# AT32M412xx_v2 register map
Vendor: Keil; Series: AT32M412; File version: 1.0
CPU: CM4 r0p1, little endian, no MPU, FPU, 4 interrupt priority bits
Registers are 32-bit, read-write, reset 0x0 unless marked. A register's access mark holds for its fields unless they carry their own. Offsets are from the block's base; [hi:lo] are bit positions; {n}, {i} and the like mark numbered series.

## USB_OTGFS_PWRCLK — USB on the go full speed
Base 0x50000E00
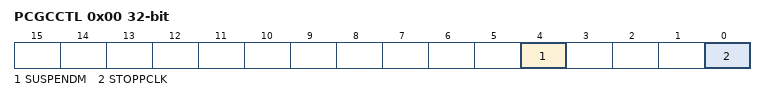
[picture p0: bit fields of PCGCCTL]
0x00 PCGCCTL — OTGFS power and clock gating control register (OTGFS_PCGCCTL)
  [4] SUSPENDM ro — PHY Suspended
  [0] STOPPCLK — Stop PHY clock

## SCFG — System configuration controller
Base 0x40013800
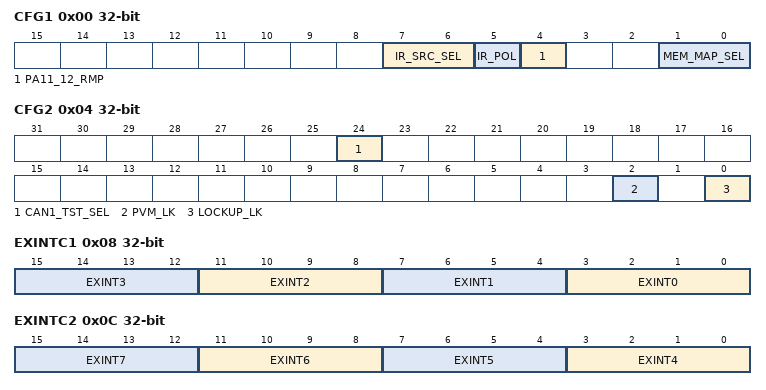
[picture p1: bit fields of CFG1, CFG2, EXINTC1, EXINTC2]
0x00 CFG1 — configuration register 1
  [7:6] IR_SRC_SEL — IR signal source selection
  [5] IR_POL — IR output polarity selection
  [4] PA11_12_RMP — PA11_12 remap to PA9_10 enable
  [1:0] MEM_MAP_SEL — Memory address mapping selection bits
0x04 CFG2 — configuration register 2
  [24] CAN1_TST_SEL — CAN timestamp clock source selection
  [2] PVM_LK — PVM lock enable
  [0] LOCKUP_LK — CM4 LOCKUP bit enable
0x08 EXINTC1 — external interrupt configuration register 1
  [4n+3:4n] EXINT{n} (n=0..3) — EXINT {n} configuration bits
0x0C EXINTC2 — external interrupt configuration register 2
  [4n-13:4n-16] EXINT{n} (n=4..7) — EXINT {n} configuration bits
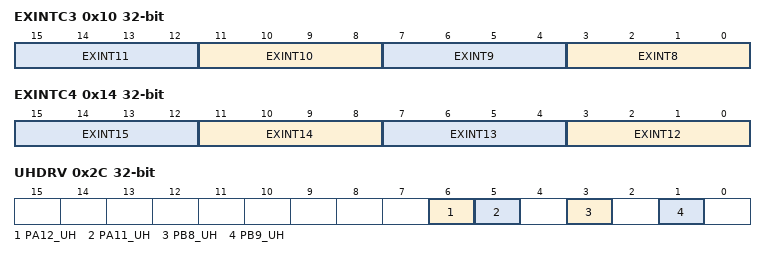
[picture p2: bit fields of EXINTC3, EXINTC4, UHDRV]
0x10 EXINTC3 — external interrupt configuration register 3
  [4n-29:4n-32] EXINT{n} (n=8..11) — EXINT {n} configuration bits
0x14 EXINTC4 — external interrupt configuration register 4
  [4n-45:4n-48] EXINT{n} (n=12..15) — EXINT {n} configuration bits
0x2C UHDRV — Ultra high drive register
  [6] PA12_UH — PA12 ultra high sourcing/sinking strength
  [5] PA11_UH — PA11 ultra high sourcing/sinking strength
  [3] PB8_UH — PB8 ultra high sourcing/sinking strength
  [1] PB9_UH — PB9 ultra high sourcing/sinking strength
0x60 IOCFG — IO config register
  [0] NRST_RMP — NRST pin remap selection
0x64 IOKEY — IO config key register
  [15:0] IOKEY — IO config key

## OP — Operational amplifiers
Base 0x40013B00
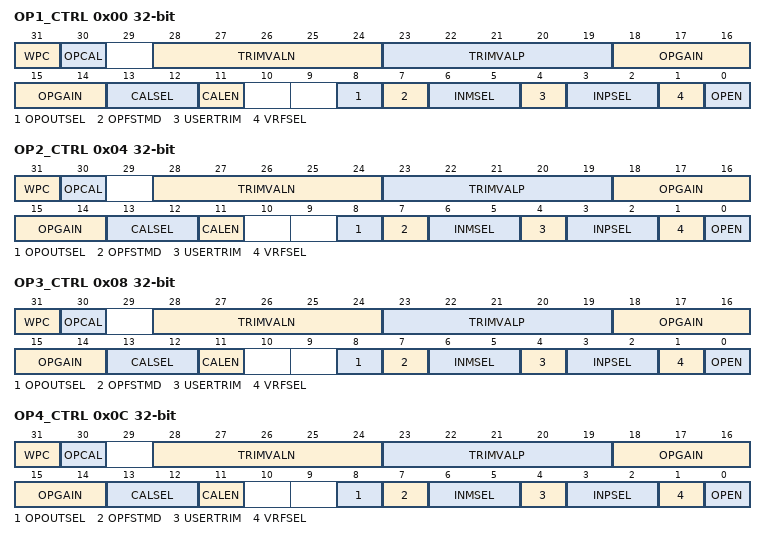
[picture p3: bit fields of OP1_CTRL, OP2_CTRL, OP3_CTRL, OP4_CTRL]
0x00 OP1_CTRL — OP1 control/status register
  [31] WPC — OP1_CTRL write protected configuration
  [30] OPCAL — Operational amplifier calibration output
  [28:24] TRIMVALN — Trim for NMOS differential pairs
  [23:19] TRIMVALP — Trim for PMOS differential pairs
  [18:14] OPGAIN — Operational amplifier Programmable amplifier gain value
  [13:12] CALSEL — Calibration selection
  [11] CALEN — Calibration mode enabled
  [8] OPOUTSEL — Operational amplifier internal output enable
  [7] OPFSTMD — Operational amplifier fast mode
  [6:5] INMSEL — Inverting input selection
  [4] USERTRIM — User trimming enable
  [3:2] INPSEL — Non inverted input selection
  [1] VRFSEL — Force internal reference on OP VINP input
  [0] OPEN — Operational amplifier Enable
0x04 OP2_CTRL — OP2 control/status register
  [31] WPC — OP2_CTRL write protected configuration
  [30] OPCAL — Operational amplifier calibration output
  [28:24] TRIMVALN — Trim for NMOS differential pairs
  [23:19] TRIMVALP — Trim for PMOS differential pairs
  [18:14] OPGAIN — Operational amplifier Programmable amplifier gain value
  [13:12] CALSEL — Calibration selection
  [11] CALEN — Calibration mode enabled
  [8] OPOUTSEL — Operational amplifier internal output enable
  [7] OPFSTMD — Operational amplifier fast mode
  [6:5] INMSEL — Inverting input selection
  [4] USERTRIM — User trimming enable
  [3:2] INPSEL — Non inverted input selection
  [1] VRFSEL — Force internal reference on OP VINP input
  [0] OPEN — Operational amplifier Enable
0x08 OP3_CTRL — OP3 control/status register
  [31] WPC — OP3_CTRL write protected configuration
  [30] OPCAL — Operational amplifier calibration output
  [28:24] TRIMVALN — Trim for NMOS differential pairs
  [23:19] TRIMVALP — Trim for PMOS differential pairs
  [18:14] OPGAIN — Operational amplifier Programmable amplifier gain value
  [13:12] CALSEL — Calibration selection
  [11] CALEN — Calibration mode enabled
  [8] OPOUTSEL — Operational amplifier internal output enable
  [7] OPFSTMD — Operational amplifier fast mode
  [6:5] INMSEL — Inverting input selection
  [4] USERTRIM — User trimming enable
  [3:2] INPSEL — Non inverted input selection
  [1] VRFSEL — Force internal reference on OP VINP input
  [0] OPEN — Operational amplifier Enable
0x0C OP4_CTRL — OP4 control/status register
  [31] WPC — OP4_CTRL write protected configuration
  [30] OPCAL — Operational amplifier calibration output
  [28:24] TRIMVALN — Trim for NMOS differential pairs
  [23:19] TRIMVALP — Trim for PMOS differential pairs
  [18:14] OPGAIN — Operational amplifier Programmable amplifier gain value
  [13:12] CALSEL — Calibration selection
  [11] CALEN — Calibration mode enabled
  [8] OPOUTSEL — Operational amplifier internal output enable
  [7] OPFSTMD — Operational amplifier fast mode
  [6:5] INMSEL — Inverting input selection
  [4] USERTRIM — User trimming enable
  [3:2] INPSEL — Non inverted input selection
  [1] VRFSEL — Force internal reference on OP VINP input
  [0] OPEN — Operational amplifier Enable
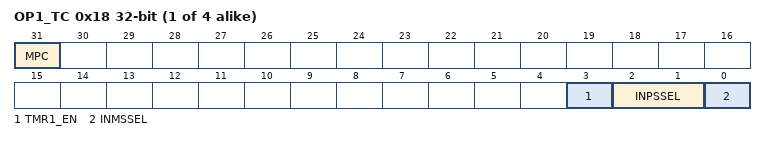
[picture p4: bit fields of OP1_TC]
{0x14+4i} OP{i}_TC (i=1..4) — OP{i} timer controlled mode register
  [31] MPC — OP{i}_TC write protected configuration
  [3] TMR1_EN — TMR1 controlled mux mode enable
  [2:1] INPSSEL — OP1 Non inverting input secondary selection
  [0] INMSSEL — OP1 inverting input secondary selection

## QSPI1 — Quad SPI Controller
Base 0xA0001000
Same registers: QSPI2 0xA0002000
0x00 CMD_W0 — Command word 0
  [31:0] SPIADR — SPI flash address
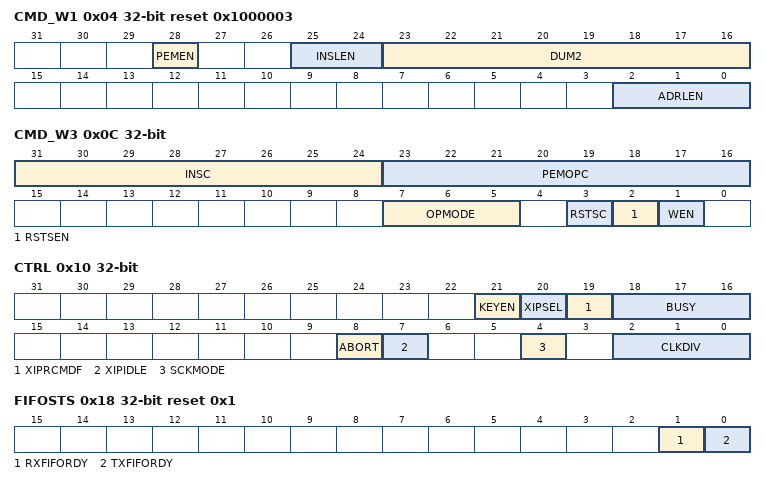
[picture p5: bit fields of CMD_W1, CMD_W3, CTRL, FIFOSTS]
0x04 CMD_W1 reset 0x1000003 — Command word 1
  [28] PEMEN — Perfrmance enhance mode enable
  [25:24] INSLEN — Instruction code length
  [23:16] DUM2 — Second dummy state cycle
  [2:0] ADRLEN — SPI address length
0x08 CMD_W2 reset 0x1000003 — Command word 2
  [31:0] DCNT — Read write data counter
0x0C CMD_W3 — Command word 3
  [31:24] INSC — Instruction code
  [23:16] PEMOPC — Performance enhance mode operate code
  [7:5] OPMODE — SPI operate mode
  [3] RSTSC — Read spi status configure
  [2] RSTSEN — Read spi status enable
  [1] WEN — Write data enable
0x10 CTRL — Control register
  [21] KEYEN — encryption key enable
  [20] XIPSEL — XIP port selection
  [19] XIPRCMDF — XIP read command flush
  [18:16] BUSY — Busy bit of spi status
  [8] ABORT — Abort instruction
  [7] XIPIDLE — XIP port idle status
  [4] SCKMODE — Sckout mode
  [2:0] CLKDIV — SPI clock divider
0x14 ACTR reset 0xF — AC timing control register
  [3:0] CSDLY — CS delay
0x18 FIFOSTS ro reset 0x1 — FIFO Status register
  [1] RXFIFORDY — RxFIFO ready status
  [0] TXFIFORDY — TxFIFO ready status
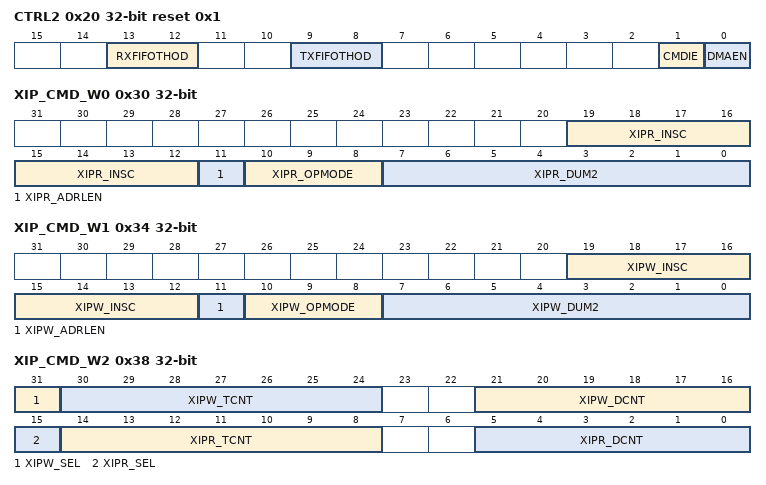
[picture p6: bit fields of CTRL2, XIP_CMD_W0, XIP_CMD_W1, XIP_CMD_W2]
0x20 CTRL2 reset 0x1 — control register 2
  [13:12] RXFIFOTHOD
  [9:8] TXFIFOTHOD
  [1] CMDIE — Command complete interrupt enable
  [0] DMAEN — DMA handshake enable
0x24 CMDSTS ro — CMD status register
  [0] CMDSTS — Command complete status
0x28 RSTS ro — SPI read status register
  [7:0] SPISTS — SPI read status
0x2C FSIZE — SPI flash size
  [31:0] SPIFSIZE
0x30 XIP_CMD_W0 — XIP command word 0
  [19:12] XIPR_INSC — XIP read instruction code
  [11] XIPR_ADRLEN — XIP read address length
  [10:8] XIPR_OPMODE — XIP read operate mode
  [7:0] XIPR_DUM2 — XIP read second dummy cycle
0x34 XIP_CMD_W1 — XIP command word 1
  [19:12] XIPW_INSC — XIP write instruction code
  [11] XIPW_ADRLEN — XIP write address length
  [10:8] XIPW_OPMODE — XIP write operate mode
  [7:0] XIPW_DUM2 — XIP write second dummy cycle
0x38 XIP_CMD_W2 — XIP command word 2
  [31] XIPW_SEL — XIP write continue mode select
  [30:24] XIPW_TCNT — XIP continue write cycle counter
  [21:16] XIPW_DCNT — XIP write data counter
  [15] XIPR_SEL — XIP read continue mode select
  [14:8] XIPR_TCNT — XIP continue read cycle counter
  [5:0] XIPR_DCNT — XIP read data counter
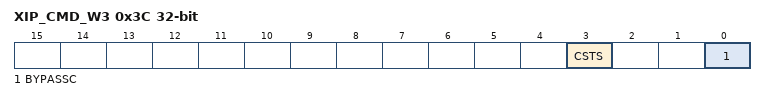
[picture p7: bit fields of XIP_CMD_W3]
0x3C XIP_CMD_W3 — XIP command word 3
  [3] CSTS — Cache status
  [0] BYPASSC — Bypass cache function
0x50 REV reset 0x10500 — Revision
  [30:0] REVISION — Revision number
0x100 DT — 32/16/8 bit data port register
